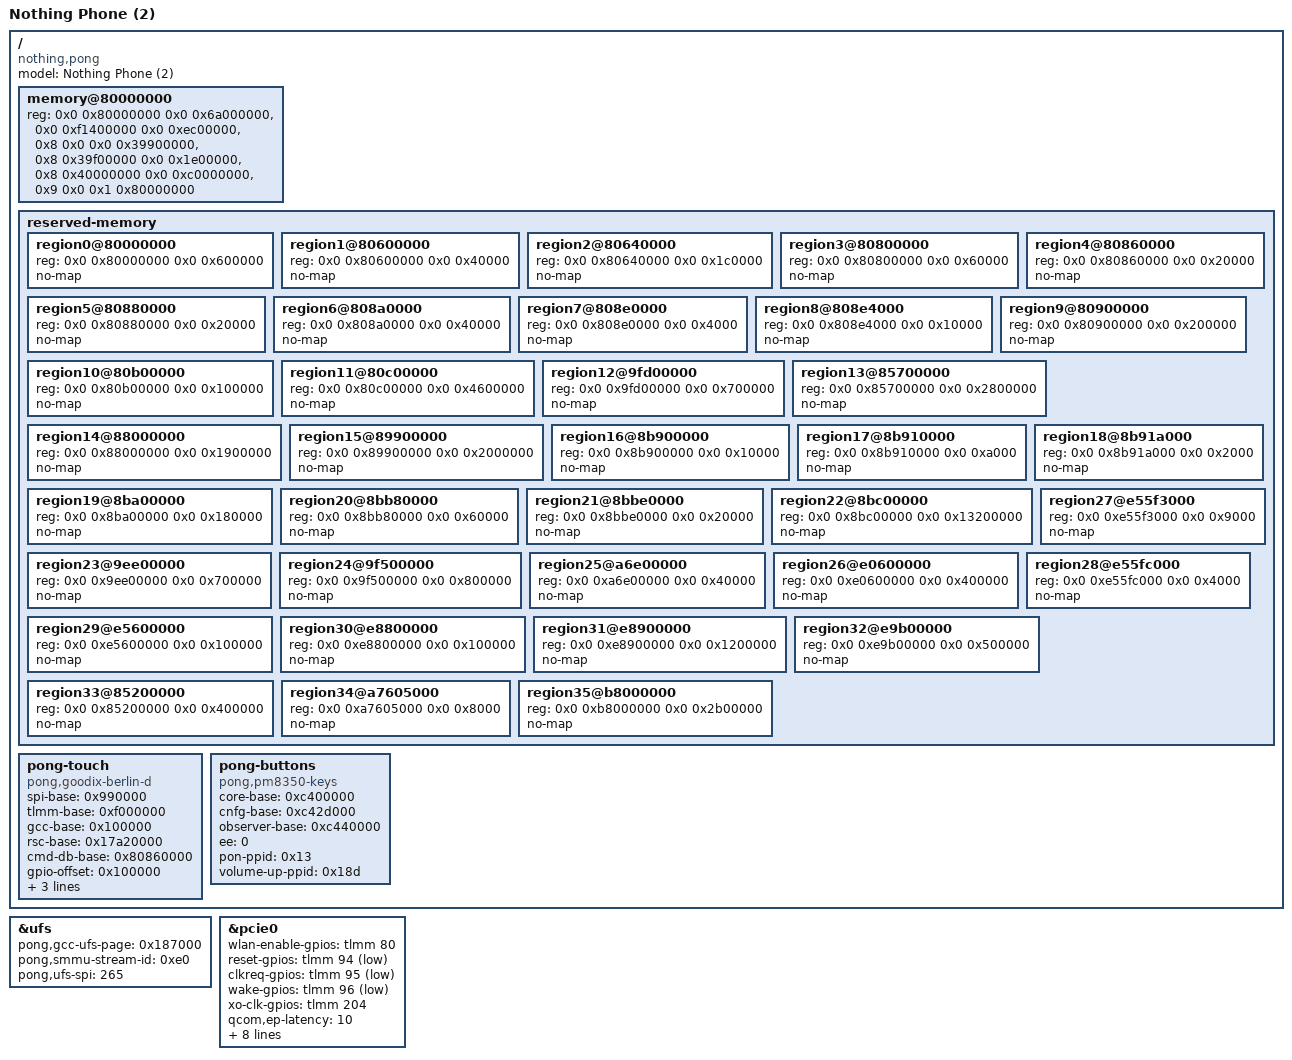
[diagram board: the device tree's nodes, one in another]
/dts-v1/;
/include/ "sm8475.dtsi"
/ {
    model = "Nothing Phone (2)";
    compatible = "nothing,pong", "qcom,sm8475";
    memory@80000000 { device_type = "memory"; reg = <0x0 0x80000000 0x0 0x6a000000>, <0x0 0xf1400000 0x0 0xec00000>, <0x8 0x0 0x0 0x39900000>, <0x8 0x39f00000 0x0 0x1e00000>, <0x8 0x40000000 0x0 0xc0000000>, <0x9 0x0 0x1 0x80000000>; };
    reserved-memory {
        #address-cells = <2>;
        #size-cells = <2>;
        ranges;
        region0@80000000 { reg = <0x0 0x80000000 0x0 0x600000>; no-map; };
        region1@80600000 { reg = <0x0 0x80600000 0x0 0x40000>; no-map; };
        region2@80640000 { reg = <0x0 0x80640000 0x0 0x1c0000>; no-map; };
        region3@80800000 { reg = <0x0 0x80800000 0x0 0x60000>; no-map; };
        region4@80860000 { reg = <0x0 0x80860000 0x0 0x20000>; no-map; };
        region5@80880000 { reg = <0x0 0x80880000 0x0 0x20000>; no-map; };
        region6@808a0000 { reg = <0x0 0x808a0000 0x0 0x40000>; no-map; };
        region7@808e0000 { reg = <0x0 0x808e0000 0x0 0x4000>; no-map; };
        region8@808e4000 { reg = <0x0 0x808e4000 0x0 0x10000>; no-map; };
        region9@80900000 { reg = <0x0 0x80900000 0x0 0x200000>; no-map; };
        region10@80b00000 { reg = <0x0 0x80b00000 0x0 0x100000>; no-map; };
        region11@80c00000 { reg = <0x0 0x80c00000 0x0 0x4600000>; no-map; };
        region12@9fd00000 { reg = <0x0 0x9fd00000 0x0 0x700000>; no-map; };
        region13@85700000 { reg = <0x0 0x85700000 0x0 0x2800000>; no-map; };
        region14@88000000 { reg = <0x0 0x88000000 0x0 0x1900000>; no-map; };
        region15@89900000 { reg = <0x0 0x89900000 0x0 0x2000000>; no-map; };
        region16@8b900000 { reg = <0x0 0x8b900000 0x0 0x10000>; no-map; };
        region17@8b910000 { reg = <0x0 0x8b910000 0x0 0xa000>; no-map; };
        region18@8b91a000 { reg = <0x0 0x8b91a000 0x0 0x2000>; no-map; };
        region19@8ba00000 { reg = <0x0 0x8ba00000 0x0 0x180000>; no-map; };
        region20@8bb80000 { reg = <0x0 0x8bb80000 0x0 0x60000>; no-map; };
        region21@8bbe0000 { reg = <0x0 0x8bbe0000 0x0 0x20000>; no-map; };
        region22@8bc00000 { reg = <0x0 0x8bc00000 0x0 0x13200000>; no-map; };
        region23@9ee00000 { reg = <0x0 0x9ee00000 0x0 0x700000>; no-map; };
        region24@9f500000 { reg = <0x0 0x9f500000 0x0 0x800000>; no-map; };
        region25@a6e00000 { reg = <0x0 0xa6e00000 0x0 0x40000>; no-map; };
        region26@e0600000 { reg = <0x0 0xe0600000 0x0 0x400000>; no-map; };
        region27@e55f3000 { reg = <0x0 0xe55f3000 0x0 0x9000>; no-map; };
        region28@e55fc000 { reg = <0x0 0xe55fc000 0x0 0x4000>; no-map; };
        region29@e5600000 { reg = <0x0 0xe5600000 0x0 0x100000>; no-map; };
        region30@e8800000 { reg = <0x0 0xe8800000 0x0 0x100000>; no-map; };
        region31@e8900000 { reg = <0x0 0xe8900000 0x0 0x1200000>; no-map; };
        region32@e9b00000 { reg = <0x0 0xe9b00000 0x0 0x500000>; no-map; };
        region33@85200000 { reg = <0x0 0x85200000 0x0 0x400000>; no-map; };
        region34@a7605000 { reg = <0x0 0xa7605000 0x0 0x8000>; no-map; };
        region35@b8000000 { reg = <0x0 0xb8000000 0x0 0x2b00000>; no-map; };
    };
    pong-touch {
        compatible = "pong,goodix-berlin-d";
        spi-base = /bits/ 64 <0x990000>;
        tlmm-base = /bits/ 64 <0xf000000>;
        gcc-base = /bits/ 64 <0x100000>;
        rsc-base = /bits/ 64 <0x17a20000>;
        cmd-db-base = /bits/ 64 <0x80860000>;
        gpio-offset = <0x100000>;
        pins = <16 17 18 19 21 20>;
        max-x = <1080>; max-y = <2412>;
    };
    pong-buttons {
        compatible = "pong,pm8350-keys";
        core-base = /bits/ 64 <0xc400000>;
        cnfg-base = /bits/ 64 <0xc42d000>;
        observer-base = /bits/ 64 <0xc440000>;
        ee = <0>; pon-ppid = <0x13>; volume-up-ppid = <0x18d>;
    };
};
&ufs { status = "okay"; pong,gcc-ufs-page = /bits/ 64 <0x187000>; pong,smmu-stream-id = <0xe0>; pong,ufs-spi = <265>; };
&pcie0 {
    status = "okay";
    wlan-enable-gpios = <&tlmm 80 0>; reset-gpios = <&tlmm 94 1>;
    clkreq-gpios = <&tlmm 95 1>; wake-gpios = <&tlmm 96 1>; xo-clk-gpios = <&tlmm 204 0>;
    qcom,ep-latency = <10>; qcom,aux-clk-freq = <20>;
    qcom,phy-status-offset = <0x214>; qcom,phy-status-bit = <6>;
    qcom,phy-power-down-offset = <0x240>;
    max-clock-frequency-hz = <0 0 0 19200000 0 0 0 0 0 0 0 100000000 0 0 0>;
    qcom,phy-sequence = <
        0x240 0x3 0
        0xc0 0x1 0
        0xcc 0x31 0
        0xd0 0x1 0
        0x60 0xff 0
        0x64 0x6 0
        0x0 0x4c 0
        0x4 0x6 0
        0xe0 0x90 0
        0xe4 0x82 0
        0xf4 0x7 0
        0x70 0x2 0
        0x10 0x2 0
        0x74 0x16 0
        0x14 0x16 0
        0x78 0x36 0
        0x18 0x36 0
        0x110 0x8 0
        0xbc 0xe 0
        0x120 0x42 0
        0x80 0xa 0
        0x84 0x1a 0
        0x20 0x14 0
        0x24 0x34 0
        0x88 0x82 0
        0x28 0x68 0
        0x90 0xab 0
        0x94 0xea 0
        0x98 0x2 0
        0x30 0xab 0
        0x34 0xaa 0
        0x38 0x2 0
        0x140 0x14 0
        0x164 0x34 0
        0x3c 0x1 0
        0x1c 0x4 0
        0x174 0x16 0
        0x1bc 0xf 0
        0x170 0xa0 0
        0x11a4 0x38 0
        0x10dc 0x11 0
        0x1160 0xbf 0
        0x1164 0xbf 0
        0x1168 0xb7 0
        0x116c 0xea 0
        0x115c 0x3f 0
        0x1174 0x5c 0
        0x1178 0x9c 0
        0x117c 0x1a 0
        0x1180 0x89 0
        0x1170 0xdc 0
        0x1188 0x94 0
        0x118c 0x5b 0
        0x1190 0x1a 0
        0x1194 0x89 0
        0x10cc 0xf0 0
        0x1008 0x9 0
        0x1014 0x5 0
        0x104c 0x8 0
        0x1050 0x8 0
        0x10d8 0xf 0
        0x1118 0x1c 0
        0x10f8 0x7 0
        0x11f8 0x8 0
        0xe84 0x15 0
        0xe90 0x3f 0
        0xee4 0x2 0
        0xe40 0x6 0
        0xe3c 0x18 0
        0x2dc 0x5 0
        0x388 0x77 0
        0x398 0xb 0
        0x3e0 0xf 0
        0x60c 0x1d 0
        0x614 0x7 0
        0x620 0xc1 0
        0x694 0x0 0
        0x3d0 0x8c 0
        0x1424 0x1 0
        0x1428 0x1 0
        0x200 0x0 0
        0x244 0x3 0
    >;
};
